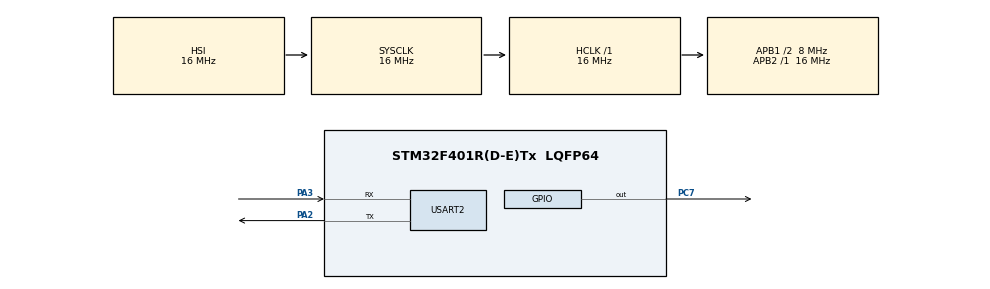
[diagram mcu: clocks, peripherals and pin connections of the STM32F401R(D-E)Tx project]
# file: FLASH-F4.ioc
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Mcu.Family=STM32F4
Mcu.Name=STM32F401R(D-E)Tx
Mcu.Package=LQFP64
NVIC.PriorityGroup=NVIC_PRIORITYGROUP_0
PA13.Mode=Serial_Wire
PA13.Signal=SYS_JTMS-SWDIO
PA14.Mode=Serial_Wire
PA14.Signal=SYS_JTCK-SWCLK
PA2.Mode=Asynchronous
PA2.Signal=USART2_TX
PA3.Mode=Asynchronous
PA3.Signal=USART2_RX
PC7.Signal=GPIO_Output
ProjectManager.HeapSize=0x200
ProjectManager.StackSize=0x400
ProjectManager.TargetToolchain=STM32CubeIDE
RCC.48MHZClocksFreq_Value=48000000
RCC.AHBFreq_Value=16000000
RCC.APB1CLKDivider=RCC_HCLK_DIV2
RCC.APB1Freq_Value=8000000
RCC.APB1TimFreq_Value=16000000
RCC.APB2Freq_Value=16000000
RCC.APB2TimFreq_Value=16000000
RCC.CortexFreq_Value=16000000
RCC.HCLKFreq_Value=16000000
RCC.HSE_VALUE=8000000
RCC.HSI_VALUE=16000000
RCC.PLLN=336
RCC.PLLP=RCC_PLLP_DIV4
RCC.PLLQ=7
RCC.SYSCLKFreq_VALUE=16000000
RCC.VCOOutputFreq_Value=336000000
USART2.VirtualMode=VM_ASYNC
board=NUCLEO-F401RE

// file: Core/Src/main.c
/* USER CODE BEGIN Header */
/**
  ******************************************************************************
  * @file           : main.c
  * @brief          : Main program body
  ******************************************************************************
  * @attention
  *
  * <h2><center>&copy; Copyright (c) 2021 STMicroelectronics.
  * All rights reserved.</center></h2>
  *
  * This software component is licensed by ST under BSD 3-Clause license,
  * the "License"; You may not use this file except in compliance with the
  * License. You may obtain a copy of the License at:
  *                        opensource.org/licenses/BSD-3-Clause
  *
  ******************************************************************************
  */
/* USER CODE END Header */
#include "main.h"

/* USER CODE BEGIN Includes */
#include "FLASH.h"
#include <string.h>
/* USER CODE END Includes */

UART_HandleTypeDef huart2;

void SystemClock_Config(void);
static void MX_GPIO_Init(void);
static void MX_USART2_UART_Init(void);

int main(void)
{
  /* USER CODE BEGIN 1 */
  char TxData[] = "Hello ";
  uint8_t RxData[20];
  volatile uint32_t  Sector1Add = 0x08004000;

  /* USER CODE END 1 */

  /* MCU Configuration--------------------------------------------------------*/

  /* Reset of all peripherals, Initializes the Flash interface and the Systick. */
  HAL_Init();

  /* Configure the system clock */
  SystemClock_Config();

  /* Initialize all configured peripherals */
  MX_GPIO_Init();
  MX_USART2_UART_Init();
  /* USER CODE BEGIN 2 */
  if ( FLASH_Write(Sector1Add, (uint8_t * )TxData, 1, strlen(TxData)) != HAL_OK)
  {
	  Error_Handler();
  }
  if ( FLASH_Read(Sector1Add, (uint8_t *) RxData, 1, strlen(TxData)) != HAL_OK)
   {
 	  Error_Handler();
   }

  HAL_UART_Transmit(&huart2, RxData, strlen((char *) RxData), HAL_MAX_DELAY);

  /* USER CODE END 2 */

  /* Infinite loop */
  while (1)
  {

  }
}

void SystemClock_Config(void)
{
  RCC_OscInitTypeDef RCC_OscInitStruct = {0};
  RCC_ClkInitTypeDef RCC_ClkInitStruct = {0};

  /** Configure the main internal regulator output voltage
  */
  __HAL_RCC_PWR_CLK_ENABLE();
  __HAL_PWR_VOLTAGESCALING_CONFIG(PWR_REGULATOR_VOLTAGE_SCALE2);
  /** Initializes the RCC Oscillators according to the specified parameters
  * in the RCC_OscInitTypeDef structure.
  */
  RCC_OscInitStruct.OscillatorType = RCC_OSCILLATORTYPE_HSI;
  RCC_OscInitStruct.HSIState = RCC_HSI_ON;
  RCC_OscInitStruct.HSICalibrationValue = RCC_HSICALIBRATION_DEFAULT;
  RCC_OscInitStruct.PLL.PLLState = RCC_PLL_NONE;
  if (HAL_RCC_OscConfig(&RCC_OscInitStruct) != HAL_OK)
  {
    Error_Handler();
  }
  /** Initializes the CPU, AHB and APB buses clocks
  */
  RCC_ClkInitStruct.ClockType = RCC_CLOCKTYPE_HCLK|RCC_CLOCKTYPE_SYSCLK
                              |RCC_CLOCKTYPE_PCLK1|RCC_CLOCKTYPE_PCLK2;
  RCC_ClkInitStruct.SYSCLKSource = RCC_SYSCLKSOURCE_HSI;
  RCC_ClkInitStruct.AHBCLKDivider = RCC_SYSCLK_DIV1;
  RCC_ClkInitStruct.APB1CLKDivider = RCC_HCLK_DIV2;
  RCC_ClkInitStruct.APB2CLKDivider = RCC_HCLK_DIV1;

  if (HAL_RCC_ClockConfig(&RCC_ClkInitStruct, FLASH_LATENCY_0) != HAL_OK)
  {
    Error_Handler();
  }
}

static void MX_USART2_UART_Init(void)
{

  huart2.Instance = USART2;
  huart2.Init.BaudRate = 115200;
  huart2.Init.WordLength = UART_WORDLENGTH_8B;
  huart2.Init.StopBits = UART_STOPBITS_1;
  huart2.Init.Parity = UART_PARITY_NONE;
  huart2.Init.Mode = UART_MODE_TX_RX;
  huart2.Init.HwFlowCtl = UART_HWCONTROL_NONE;
  huart2.Init.OverSampling = UART_OVERSAMPLING_16;
  if (HAL_UART_Init(&huart2) != HAL_OK)
  {
    Error_Handler();
  }

}

static void MX_GPIO_Init(void)
{
  GPIO_InitTypeDef GPIO_InitStruct = {0};

  /* GPIO Ports Clock Enable */
  __HAL_RCC_GPIOA_CLK_ENABLE();
  __HAL_RCC_GPIOC_CLK_ENABLE();

  /*Configure GPIO pin Output Level */
  HAL_GPIO_WritePin(GPIOC, GPIO_PIN_7, GPIO_PIN_RESET);

  /*Configure GPIO pin : PC7 */
  GPIO_InitStruct.Pin = GPIO_PIN_7;
  GPIO_InitStruct.Mode = GPIO_MODE_OUTPUT_PP;
  GPIO_InitStruct.Pull = GPIO_NOPULL;
  GPIO_InitStruct.Speed = GPIO_SPEED_FREQ_LOW;
  HAL_GPIO_Init(GPIOC, &GPIO_InitStruct);

}

void Error_Handler(void)
{
  /* USER CODE BEGIN Error_Handler_Debug */
  /* User can add his own implementation to report the HAL error return state */
	uint8_t count = 30;

		while ( count > 0 )
		{
			HAL_GPIO_TogglePin(GPIOC, GPIO_PIN_7);
			HAL_Delay(100);
			count --;
		}
  /* USER CODE END Error_Handler_Debug */
}

/************************ (C) COPYRIGHT STMicroelectronics *****END OF FILE****/
